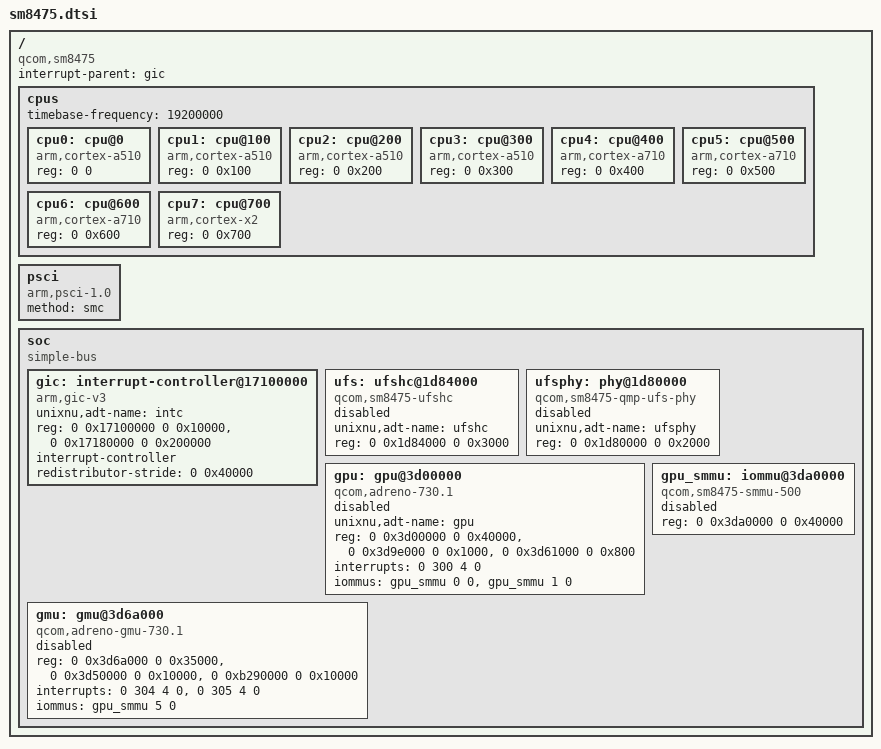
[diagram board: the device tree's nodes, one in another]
// SPDX-License-Identifier: BSD-3-Clause
// Qualcomm SM8475 (Snapdragon 8+ Gen 1, "cape" / "taro"), shared resources.
//
// Every value here was taken from one of two places, never invented:
//   * the phone's own vendor_boot device tree (qcom,cape-v2, extracted from the
//     OS1.0.16.0.ULFCNXM fastboot ROM) -- UFS, GPU/GMU/GPU-SMMU, GIC;
//   * the running phone over adb (/sys/bus/platform/devices, whose node names carry
//     the base addresses) -- cross-checked against the above.
//
// Cross-check with UniXNU-ace2 (OnePlus Ace 2, same SoC): GIC 0x17100000/0x17180000
// stride 0x40000, UFS 0x1d84000/0x1d80000, framebuffer 0xb8000000 -- all agree.
//
// CPU topology is SM8450/SM8475's 1+3+4: one Cortex-X2, three A710, four A510.
// This differs from SM8550's 1+2+2+3 and must not be copied from there.

/ {
    compatible = "qcom,sm8475";
    #address-cells = <2>;
    #size-cells = <2>;
    interrupt-parent = <&gic>;

    cpus {
        #address-cells = <2>;
        #size-cells = <0>;
        timebase-frequency = <19200000>;
        cpu0: cpu@0 { device_type = "cpu"; compatible = "arm,cortex-a510"; reg = <0 0>; };
        cpu1: cpu@100 { device_type = "cpu"; compatible = "arm,cortex-a510"; reg = <0 0x100>; };
        cpu2: cpu@200 { device_type = "cpu"; compatible = "arm,cortex-a510"; reg = <0 0x200>; };
        cpu3: cpu@300 { device_type = "cpu"; compatible = "arm,cortex-a510"; reg = <0 0x300>; };
        cpu4: cpu@400 { device_type = "cpu"; compatible = "arm,cortex-a710"; reg = <0 0x400>; };
        cpu5: cpu@500 { device_type = "cpu"; compatible = "arm,cortex-a710"; reg = <0 0x500>; };
        cpu6: cpu@600 { device_type = "cpu"; compatible = "arm,cortex-a710"; reg = <0 0x600>; };
        cpu7: cpu@700 { device_type = "cpu"; compatible = "arm,cortex-x2";   reg = <0 0x700>; };
    };

    psci { compatible = "arm,psci-1.0"; method = "smc"; };

    soc {
        compatible = "simple-bus";
        #address-cells = <2>;
        #size-cells = <2>;
        ranges;

        // Phone: intc: interrupt-controller@17100000  (GICD +0x10000, GICR +0x200000)
        gic: interrupt-controller@17100000 {
            compatible = "arm,gic-v3";
            unixnu,adt-name = "intc";
            reg = <0 0x17100000 0 0x10000>, <0 0x17180000 0 0x200000>;
            #interrupt-cells = <4>;
            #address-cells = <0>;
            interrupt-controller;
            redistributor-stride = <0 0x40000>;
        };

        // Phone: 1d84000.ufshc
        ufs: ufshc@1d84000 {
            compatible = "qcom,sm8475-ufshc";
            unixnu,adt-name = "ufshc";
            reg = <0 0x1d84000 0 0x3000>;
            status = "disabled";
        };

        // Phone: 1d80000.ufsphy_mem -- v6 register window, 0x2000 bytes (not SM8450's 0x1d87000)
        ufsphy: phy@1d80000 {
            compatible = "qcom,sm8475-qmp-ufs-phy";
            unixnu,adt-name = "ufsphy";
            reg = <0 0x1d80000 0 0x2000>;
            status = "disabled";
        };

        // Phone: 3d00000.qcom,kgsl-3d0 -- Adreno 730v3
        gpu: gpu@3d00000 {
            compatible = "qcom,adreno-730.1", "qcom,adreno";
            unixnu,adt-name = "gpu";
            reg = <0 0x3d00000 0 0x40000>,
                  <0 0x3d9e000 0 0x1000>,
                  <0 0x3d61000 0 0x800>;
            reg-names = "kgsl_3d0_reg_memory", "cx_mem", "cx_dbgc";
            interrupts = <0 300 4 0>;
            iommus = <&gpu_smmu 0 0>, <&gpu_smmu 1 0>;
            status = "disabled";
        };

        // SM8475 GMU. The third window is 0xb290000 -- SM8550's GMU uses 0xb280000,
        // so this value cannot be copied from sm8550.dtsi.
        gmu: gmu@3d6a000 {
            compatible = "qcom,adreno-gmu-730.1", "qcom,adreno-gmu";
            reg = <0 0x3d6a000 0 0x35000>,
                  <0 0x3d50000 0 0x10000>,
                  <0 0xb290000 0 0x10000>;
            reg-names = "gmu", "rscc", "gmu_pdc";
            interrupts = <0 304 4 0>, <0 305 4 0>;
            interrupt-names = "hfi", "gmu";
            iommus = <&gpu_smmu 5 0>;
            status = "disabled";
        };

        // Phone: 3da0000.kgsl-smmu
        gpu_smmu: iommu@3da0000 {
            compatible = "qcom,sm8475-smmu-500", "qcom,adreno-smmu", "qcom,smmu-500", "arm,mmu-500";
            reg = <0 0x3da0000 0 0x40000>;
            #iommu-cells = <2>;
            status = "disabled";
        };
    };
};
